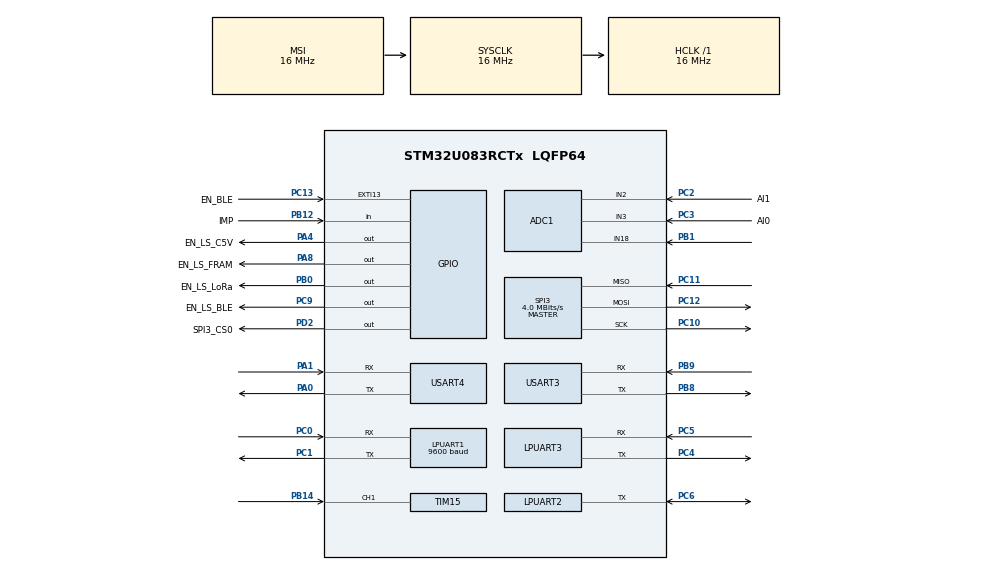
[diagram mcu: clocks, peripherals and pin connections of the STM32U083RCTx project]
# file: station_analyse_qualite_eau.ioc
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ADC1.DMAContinuousRequests=ENABLE
ADC1.LowPowerAutoPowerOff=ENABLE
ADC1.LowPowerAutoWait=ENABLE
ADC1.NbrOfConversion=1
ADC1.NbrOfConversionFlag=0
ADC1.OversamplingMode=ENABLE
ADC1.Ratio=ADC_OVERSAMPLING_RATIO_16
ADC1.RightBitShift=ADC_RIGHTBITSHIFT_4
ADC1.SelectedChannel=ADC_CHANNEL_2|ADC_CHANNEL_3|ADC_CHANNEL_VREFINT|ADC_CHANNEL_18
ADC1.Sequencer=NOT_FULLY_CONFIGURABLE
ADC1.master=1
Dma.ADC1.3.Direction=DMA_PERIPH_TO_MEMORY
Dma.ADC1.3.EventEnable=DISABLE
Dma.ADC1.3.Instance=DMA1_Channel4
Dma.ADC1.3.MemDataAlignment=DMA_MDATAALIGN_HALFWORD
Dma.ADC1.3.MemInc=DMA_MINC_ENABLE
Dma.ADC1.3.Mode=DMA_NORMAL
Dma.ADC1.3.PeriphDataAlignment=DMA_PDATAALIGN_HALFWORD
Dma.ADC1.3.PeriphInc=DMA_PINC_DISABLE
Dma.ADC1.3.Polarity=HAL_DMAMUX_REQ_GEN_RISING
Dma.ADC1.3.Priority=DMA_PRIORITY_LOW
Dma.ADC1.3.RequestNumber=1
Dma.ADC1.3.SignalID=NONE
Dma.ADC1.3.SyncEnable=DISABLE
Dma.ADC1.3.SyncPolarity=HAL_DMAMUX_SYNC_NO_EVENT
Dma.ADC1.3.SyncRequestNumber=1
Dma.ADC1.3.SyncSignalID=NONE
Dma.LPUART1_RX.2.Direction=DMA_PERIPH_TO_MEMORY
Dma.LPUART1_RX.2.EventEnable=DISABLE
Dma.LPUART1_RX.2.Instance=DMA1_Channel3
Dma.LPUART1_RX.2.MemDataAlignment=DMA_MDATAALIGN_BYTE
Dma.LPUART1_RX.2.MemInc=DMA_MINC_ENABLE
Dma.LPUART1_RX.2.Mode=DMA_NORMAL
Dma.LPUART1_RX.2.PeriphDataAlignment=DMA_PDATAALIGN_BYTE
Dma.LPUART1_RX.2.PeriphInc=DMA_PINC_DISABLE
Dma.LPUART1_RX.2.Polarity=HAL_DMAMUX_REQ_GEN_RISING
Dma.LPUART1_RX.2.Priority=DMA_PRIORITY_LOW
Dma.LPUART1_RX.2.RequestNumber=1
Dma.LPUART1_RX.2.SignalID=NONE
Dma.LPUART1_RX.2.SyncEnable=DISABLE
Dma.LPUART1_RX.2.SyncPolarity=HAL_DMAMUX_SYNC_NO_EVENT
Dma.LPUART1_RX.2.SyncRequestNumber=1
Dma.LPUART1_RX.2.SyncSignalID=NONE
Dma.LPUART2_RX.1.Direction=DMA_PERIPH_TO_MEMORY
Dma.LPUART2_RX.1.EventEnable=DISABLE
Dma.LPUART2_RX.1.Instance=DMA1_Channel2
Dma.LPUART2_RX.1.MemDataAlignment=DMA_MDATAALIGN_BYTE
Dma.LPUART2_RX.1.MemInc=DMA_MINC_ENABLE
Dma.LPUART2_RX.1.Mode=DMA_NORMAL
Dma.LPUART2_RX.1.PeriphDataAlignment=DMA_PDATAALIGN_BYTE
Dma.LPUART2_RX.1.PeriphInc=DMA_PINC_DISABLE
Dma.LPUART2_RX.1.Polarity=HAL_DMAMUX_REQ_GEN_RISING
Dma.LPUART2_RX.1.Priority=DMA_PRIORITY_LOW
Dma.LPUART2_RX.1.RequestNumber=1
Dma.LPUART2_RX.1.SignalID=NONE
Dma.LPUART2_RX.1.SyncEnable=DISABLE
Dma.LPUART2_RX.1.SyncPolarity=HAL_DMAMUX_SYNC_NO_EVENT
Dma.LPUART2_RX.1.SyncRequestNumber=1
Dma.LPUART2_RX.1.SyncSignalID=NONE
Dma.LPUART2_TX.0.Direction=DMA_MEMORY_TO_PERIPH
Dma.LPUART2_TX.0.EventEnable=DISABLE
Dma.LPUART2_TX.0.Instance=DMA1_Channel1
Dma.LPUART2_TX.0.MemDataAlignment=DMA_MDATAALIGN_BYTE
Dma.LPUART2_TX.0.MemInc=DMA_MINC_ENABLE
Dma.LPUART2_TX.0.Mode=DMA_NORMAL
Dma.LPUART2_TX.0.PeriphDataAlignment=DMA_PDATAALIGN_BYTE
Dma.LPUART2_TX.0.PeriphInc=DMA_PINC_DISABLE
Dma.LPUART2_TX.0.Polarity=HAL_DMAMUX_REQ_GEN_RISING
Dma.LPUART2_TX.0.Priority=DMA_PRIORITY_LOW
Dma.LPUART2_TX.0.RequestNumber=1
Dma.LPUART2_TX.0.SignalID=NONE
Dma.LPUART2_TX.0.SyncEnable=DISABLE
Dma.LPUART2_TX.0.SyncPolarity=HAL_DMAMUX_SYNC_NO_EVENT
Dma.LPUART2_TX.0.SyncRequestNumber=1
Dma.LPUART2_TX.0.SyncSignalID=NONE
Dma.Request0=LPUART2_TX
Dma.Request1=LPUART2_RX
Dma.Request2=LPUART1_RX
Dma.Request3=ADC1
Dma.Request4=SPI3_RX
Dma.Request5=SPI3_TX
Dma.Request6=USART3_RX
Dma.Request7=USART3_TX
Dma.SPI3_RX.4.Direction=DMA_PERIPH_TO_MEMORY
Dma.SPI3_RX.4.EventEnable=DISABLE
Dma.SPI3_RX.4.Instance=DMA1_Channel5
Dma.SPI3_RX.4.MemDataAlignment=DMA_MDATAALIGN_BYTE
Dma.SPI3_RX.4.MemInc=DMA_MINC_ENABLE
Dma.SPI3_RX.4.Mode=DMA_NORMAL
Dma.SPI3_RX.4.PeriphDataAlignment=DMA_PDATAALIGN_BYTE
Dma.SPI3_RX.4.PeriphInc=DMA_PINC_DISABLE
Dma.SPI3_RX.4.Polarity=HAL_DMAMUX_REQ_GEN_RISING
Dma.SPI3_RX.4.Priority=DMA_PRIORITY_LOW
Dma.SPI3_RX.4.RequestNumber=1
Dma.SPI3_RX.4.SignalID=NONE
Dma.SPI3_RX.4.SyncEnable=DISABLE
Dma.SPI3_RX.4.SyncPolarity=HAL_DMAMUX_SYNC_NO_EVENT
Dma.SPI3_RX.4.SyncRequestNumber=1
Dma.SPI3_RX.4.SyncSignalID=NONE
Dma.SPI3_TX.5.Direction=DMA_MEMORY_TO_PERIPH
Dma.SPI3_TX.5.EventEnable=DISABLE
Dma.SPI3_TX.5.Instance=DMA1_Channel6
Dma.SPI3_TX.5.MemDataAlignment=DMA_MDATAALIGN_BYTE
Dma.SPI3_TX.5.MemInc=DMA_MINC_ENABLE
Dma.SPI3_TX.5.Mode=DMA_NORMAL
Dma.SPI3_TX.5.PeriphDataAlignment=DMA_PDATAALIGN_BYTE
Dma.SPI3_TX.5.PeriphInc=DMA_PINC_DISABLE
Dma.SPI3_TX.5.Polarity=HAL_DMAMUX_REQ_GEN_RISING
Dma.SPI3_TX.5.Priority=DMA_PRIORITY_LOW
Dma.SPI3_TX.5.RequestNumber=1
Dma.SPI3_TX.5.SignalID=NONE
Dma.SPI3_TX.5.SyncEnable=DISABLE
Dma.SPI3_TX.5.SyncPolarity=HAL_DMAMUX_SYNC_NO_EVENT
Dma.SPI3_TX.5.SyncRequestNumber=1
Dma.SPI3_TX.5.SyncSignalID=NONE
Dma.USART3_RX.6.Direction=DMA_PERIPH_TO_MEMORY
Dma.USART3_RX.6.EventEnable=DISABLE
Dma.USART3_RX.6.Instance=DMA1_Channel7
Dma.USART3_RX.6.MemDataAlignment=DMA_MDATAALIGN_BYTE
Dma.USART3_RX.6.MemInc=DMA_MINC_ENABLE
Dma.USART3_RX.6.Mode=DMA_NORMAL
Dma.USART3_RX.6.PeriphDataAlignment=DMA_PDATAALIGN_BYTE
Dma.USART3_RX.6.PeriphInc=DMA_PINC_DISABLE
Dma.USART3_RX.6.Polarity=HAL_DMAMUX_REQ_GEN_RISING
Dma.USART3_RX.6.Priority=DMA_PRIORITY_LOW
Dma.USART3_RX.6.RequestNumber=1
Dma.USART3_RX.6.SignalID=NONE
Dma.USART3_RX.6.SyncEnable=DISABLE
Dma.USART3_RX.6.SyncPolarity=HAL_DMAMUX_SYNC_NO_EVENT
Dma.USART3_RX.6.SyncRequestNumber=1
Dma.USART3_RX.6.SyncSignalID=NONE
Dma.USART3_TX.7.Direction=DMA_MEMORY_TO_PERIPH
Dma.USART3_TX.7.EventEnable=DISABLE
Dma.USART3_TX.7.Instance=DMA2_Channel1
Dma.USART3_TX.7.MemDataAlignment=DMA_MDATAALIGN_BYTE
Dma.USART3_TX.7.MemInc=DMA_MINC_ENABLE
Dma.USART3_TX.7.Mode=DMA_NORMAL
Dma.USART3_TX.7.PeriphDataAlignment=DMA_PDATAALIGN_BYTE
Dma.USART3_TX.7.PeriphInc=DMA_PINC_DISABLE
Dma.USART3_TX.7.Polarity=HAL_DMAMUX_REQ_GEN_RISING
Dma.USART3_TX.7.Priority=DMA_PRIORITY_LOW
Dma.USART3_TX.7.RequestNumber=1
Dma.USART3_TX.7.SignalID=NONE
Dma.USART3_TX.7.SyncEnable=DISABLE
Dma.USART3_TX.7.SyncPolarity=HAL_DMAMUX_SYNC_NO_EVENT
Dma.USART3_TX.7.SyncRequestNumber=1
Dma.USART3_TX.7.SyncSignalID=NONE
LPTIM1.ClockPrescaler=LPTIM_PRESCALER_DIV32
LPTIM1.Period=65500
LPUART1.BaudRate=9600
LPUART1.SwapParam=UART_ADVFEATURE_SWAP_ENABLE
LPUART2.BaudRate=9600
LPUART2.SwapParam=UART_ADVFEATURE_SWAP_DISABLE
LPUART2.WordLength=UART_WORDLENGTH_8B
Mcu.Family=STM32U0
Mcu.Name=STM32U083RCTx
Mcu.Package=LQFP64
NUCLEO-U083RC.BUTTON=0
NUCLEO-U083RC.LD4=true
NUCLEO-U083RC.VCP=true
NVIC.ADC_COMP1_2_IRQn=true\:0\:0\:false\:false\:true\:true\:true\:true
NVIC.DMA1_Ch4_7_DMA2_Ch1_5_DMAMUX_OVR_IRQn=true\:0\:0\:false\:false\:true\:false\:true\:true
NVIC.DMA1_Channel1_IRQn=true\:0\:0\:false\:false\:true\:false\:true\:true
NVIC.DMA1_Channel2_3_IRQn=true\:0\:0\:false\:false\:true\:false\:true\:true
NVIC.EXTI4_15_IRQn=true\:0\:0\:false\:false\:true\:false\:true\:true
NVIC.PriorityGroup=NVIC_PRIORITYGROUP_2
NVIC.RTC_TAMP_IRQn=true\:0\:0\:false\:false\:true\:true\:true\:true
NVIC.SPI2_3_IRQn=true\:0\:0\:false\:false\:true\:true\:true\:true
NVIC.TIM6_DAC_LPTIM1_IRQn=true\:0\:0\:false\:false\:true\:true\:true\:true
NVIC.USART2_LPUART2_IRQn=true\:0\:0\:false\:false\:true\:true\:true\:true
NVIC.USART3_LPUART1_IRQn=true\:0\:0\:false\:false\:true\:true\:true\:true
PA0.Mode=Asynchronous
PA0.Signal=USART4_TX
PA1.Mode=Asynchronous
PA1.Signal=USART4_RX
PA13\ (SWDIO).GPIO_Label=SWDIO
PA13\ (SWDIO).Signal=DEBUG_JTMS-SWDIO
PA14\ (SWCLK).GPIO_Label=SWCLK
PA14\ (SWCLK).Signal=DEBUG_JTCK-SWCLK
PA2.Signal=USART2_TX
PA3.Signal=USART2_RX
PA4.GPIO_Label=EN_LS_C5V
PA4.Signal=GPIO_Output
PA8.GPIO_Label=EN_LS_FRAM
PA8.Signal=GPIO_Output
PB0.GPIO_Label=EN_LS_LoRa
PB0.Signal=GPIO_Output
PB1.Mode=IN18
PB1.Signal=ADC1_IN18
PB12.GPIO_Label=IMP
PB12.Signal=GPIO_Input
PB14.Signal=S_TIM15_CH1
PB8.Mode=Asynchronous
PB8.Signal=USART3_TX
PB9.Mode=Asynchronous
PB9.Signal=USART3_RX
PC0.Mode=Asynchronous
PC0.Signal=LPUART1_RX
PC1.Mode=Asynchronous
PC1.Signal=LPUART1_TX
PC10.Mode=Full_Duplex_Master
PC10.Signal=SPI3_SCK
PC11.Mode=Full_Duplex_Master
PC11.Signal=SPI3_MISO
PC12.Mode=Full_Duplex_Master
PC12.Signal=SPI3_MOSI
PC13.GPIO_Label=EN_BLE
PC13.GPIO_ModeDefaultEXTI=GPIO_MODE_IT_FALLING
PC13.GPIO_PuPd=GPIO_PULLUP
PC13.Signal=GPXTI13
PC14-OSC32_IN.GPIO_Label=OSC32_IN
PC14-OSC32_IN.Mode=LSE-External-Oscillator
PC14-OSC32_IN.Signal=RCC_OSC32_IN
PC15-OSC32_OUT.GPIO_Label=OSC32_OUT
PC15-OSC32_OUT.Mode=LSE-External-Oscillator
PC15-OSC32_OUT.Signal=RCC_OSC32_OUT
PC2.GPIO_Label=AI1
PC2.Signal=SharedAnalog_PC2
PC3.GPIO_Label=AI0
PC3.Signal=SharedAnalog_PC3
PC4.Mode=Asynchronous
PC4.Signal=LPUART3_TX
PC5.Mode=Asynchronous
PC5.Signal=LPUART3_RX
PC6.GPIO_PuPdOD=GPIO_NOPULL
PC6.Mode=Half_duplex(single_wire_mode)
PC6.Signal=LPUART2_TX
PC9.GPIO_Label=EN_LS_BLE
PC9.Signal=GPIO_Output
PD2.GPIO_Label=SPI3_CS0
PD2.Signal=GPIO_Output
PF0-OSC_IN.GPIO_Label=OSC_IN
PF0-OSC_IN.Signal=RCC_OSC_IN
PF1-OSC_OUT.GPIO_Label=OSC_OUT
PF1-OSC_OUT.Signal=RCC_OSC_OUT
ProjectManager.HeapSize=0x200
ProjectManager.StackSize=0x400
ProjectManager.TargetToolchain=STM32CubeIDE
RCC.ADCFreq_Value=16000000
RCC.AHBFreq_Value=16000000
RCC.CortexFreq_Value=16000000
RCC.HCLKFreq_Value=16000000
RCC.HSE_VALUE=4000000
RCC.HSI48_VALUE=48000000
RCC.HSI_VALUE=16000000
RCC.LPUART1CLockSelection=RCC_LPUART1CLKSOURCE_LSE
RCC.MSIAutoCalibration=ENABLED
RCC.MSIClockRangeVal=RCC_MSIRANGE_8
RCC.MSI_VALUE=16000000
RCC.RTCClockSelection=RCC_RTCCLKSOURCE_LSE
RCC.SYSCLKFreq_VALUE=16000000
RCC.SYSCLKSource=RCC_SYSCLKSOURCE_MSI
RCC.USBCLockSelection=RCC_USBCLKSOURCE_HSI48
RCC.USBFreq_Value=48000000
RCC.VCOOutputFreq_Value=64000000
RTC.WakeUpClock-WakeUp=RTC_WAKEUPCLOCK_CK_SPRE_16BITS
SH.S_TIM15_CH1.0=TIM15_CH1,Input_Capture1_from_TI1
SH.SharedAnalog_PC2.0=GPIO_Analog
SH.SharedAnalog_PC2.1=ADC1_IN2,IN2
SH.SharedAnalog_PC3.0=GPIO_Analog
SH.SharedAnalog_PC3.1=ADC1_IN3,IN3
SPI3.BaudRatePrescaler=SPI_BAUDRATEPRESCALER_4
SPI3.CalculateBaudRate=4.0 MBits/s
SPI3.DataSize=SPI_DATASIZE_8BIT
SPI3.Direction=SPI_DIRECTION_2LINES
SPI3.Mode=SPI_MODE_MASTER
SPI3.VirtualType=VM_MASTER
TIM15.Channel-Input_Capture1_from_TI1=TIM_CHANNEL_1
USART3.VirtualMode-Asynchronous=VM_ASYNC
USART4.VirtualMode-Asynchronous=VM_ASYNC
VP_ADC1_Vref_Input.Mode=IN-Vrefint
VP_LPTIM1_VS_LPTIM_counterModeInternalClock.Mode=Counts__internal_clock_event_00
VP_NUCLEO-U083RC_VS_BSP_COMMON.Mode=COMMON
VP_PWR_VS_SECSignals.Mode=Security/Privilege
VP_RTC_VS_RTC_Activate.Mode=RTC_Enabled
VP_RTC_VS_RTC_WakeUp_intern.Mode=WakeUp
board=NUCLEO-U083RC

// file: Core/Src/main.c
/* USER CODE BEGIN Header */
/**
  ******************************************************************************
  * @file           : main.c
  * @brief          : Main program body
  ******************************************************************************
  * @attention
  *
  * Copyright (c) 2026 STMicroelectronics.
  * All rights reserved.
  *
  * This software is licensed under terms that can be found in the LICENSE file
  * in the root directory of this software component.
  * If no LICENSE file comes with this software, it is provided AS-IS.
  *
  ******************************************************************************
  */
/* USER CODE END Header */
#include "main.h"
#include "adc.h"
#include "dma.h"
#include "lptim.h"
#include "usart.h"
#include "rtc.h"
#include "spi.h"
#include "tim.h"
#include "gpio.h"

/* USER CODE BEGIN Includes */
#include "app_main_test.h"
/* USER CODE END Includes */

COM_InitTypeDef BspCOMInit;

void SystemClock_Config(void);

int main(void)
{

  /* MCU Configuration--------------------------------------------------------*/

  /* Reset of all peripherals, Initializes the Flash interface and the Systick. */
  HAL_Init();

  /* Configure the system clock */
  SystemClock_Config();

  /* Initialize all configured peripherals */
  MX_GPIO_Init();
  MX_DMA_Init();
  MX_LPUART2_UART_Init();
  MX_LPUART1_UART_Init();
  MX_RTC_Init();
  MX_ADC1_Init();
  MX_USART3_UART_Init();
  MX_LPTIM1_Init();
  MX_SPI3_Init();
  MX_LPUART3_UART_Init();
  MX_USART4_UART_Init();
  MX_TIM15_Init();

  /* Initialize leds */
  BSP_LED_Init(LED_GREEN);

  /* Initialize COM1 port (115200, 8 bits (7-bit data + 1 stop bit), no parity */
  BspCOMInit.BaudRate   = 115200;
  BspCOMInit.WordLength = COM_WORDLENGTH_8B;
  BspCOMInit.StopBits   = COM_STOPBITS_1;
  BspCOMInit.Parity     = COM_PARITY_NONE;
  BspCOMInit.HwFlowCtl  = COM_HWCONTROL_NONE;
  if (BSP_COM_Init(COM1, &BspCOMInit) != BSP_ERROR_NONE)
  {
    Error_Handler();
  }

  /* Infinite loop */
  /* USER CODE BEGIN WHILE */

  printf("DEBUT DU SETUPSETUP\n\n");
  setup();
  printf("DEBUT DU WHILE\r\n\n");
  while (1)
  {
    /* USER CODE END WHILE */

    /* USER CODE BEGIN 3 */
	loop();
  }
  /* USER CODE END 3 */
}

void SystemClock_Config(void)
{
  RCC_OscInitTypeDef RCC_OscInitStruct = {0};
  RCC_ClkInitTypeDef RCC_ClkInitStruct = {0};

  /** Configure the main internal regulator output voltage
  */
  HAL_PWREx_ControlVoltageScaling(PWR_REGULATOR_VOLTAGE_SCALE2);

  /** Configure LSE Drive Capability
  */
  HAL_PWR_EnableBkUpAccess();
  __HAL_RCC_LSEDRIVE_CONFIG(RCC_LSEDRIVE_LOW);

  /** Initializes the RCC Oscillators according to the specified parameters
  * in the RCC_OscInitTypeDef structure.
  */
  RCC_OscInitStruct.OscillatorType = RCC_OSCILLATORTYPE_LSI|RCC_OSCILLATORTYPE_LSE
                              |RCC_OSCILLATORTYPE_MSI;
  RCC_OscInitStruct.LSEState = RCC_LSE_ON;
  RCC_OscInitStruct.LSIState = RCC_LSI_ON;
  RCC_OscInitStruct.MSIState = RCC_MSI_ON;
  RCC_OscInitStruct.MSICalibrationValue = RCC_MSICALIBRATION_DEFAULT;
  RCC_OscInitStruct.MSIClockRange = RCC_MSIRANGE_8;
  RCC_OscInitStruct.PLL.PLLState = RCC_PLL_NONE;
  if (HAL_RCC_OscConfig(&RCC_OscInitStruct) != HAL_OK)
  {
    Error_Handler();
  }

  /** Initializes the CPU, AHB and APB buses clocks
  */
  RCC_ClkInitStruct.ClockType = RCC_CLOCKTYPE_HCLK|RCC_CLOCKTYPE_SYSCLK
                              |RCC_CLOCKTYPE_PCLK1;
  RCC_ClkInitStruct.SYSCLKSource = RCC_SYSCLKSOURCE_MSI;
  RCC_ClkInitStruct.AHBCLKDivider = RCC_SYSCLK_DIV1;
  RCC_ClkInitStruct.APB1CLKDivider = RCC_HCLK_DIV1;

  if (HAL_RCC_ClockConfig(&RCC_ClkInitStruct, FLASH_LATENCY_1) != HAL_OK)
  {
    Error_Handler();
  }

  /** Enable MSI Auto calibration
  */
  HAL_RCCEx_EnableMSIPLLMode();
}

void Error_Handler(void)
{
  __disable_irq();
  while (1)
  {
  }
}
